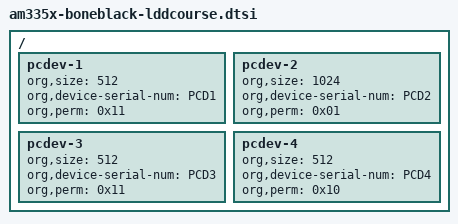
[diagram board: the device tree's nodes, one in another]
/ {
	pcdev-1 {
		org,size = <512>;
		org,device-serial-num = "PCD1";
		org,perm = <0x11>;
	};
	pcdev-2 {
		org,size = <1024>;
		org,device-serial-num = "PCD2";
		org,perm = <0x01>;
	};

	pcdev-3 {
		org,size = <512>;
		org,device-serial-num = "PCD3";
		org,perm = <0x11>;
	};
	pcdev-4 {
		org,size = <512>;
		org,device-serial-num = "PCD4";
		org,perm = <0x10>;
	};
};
